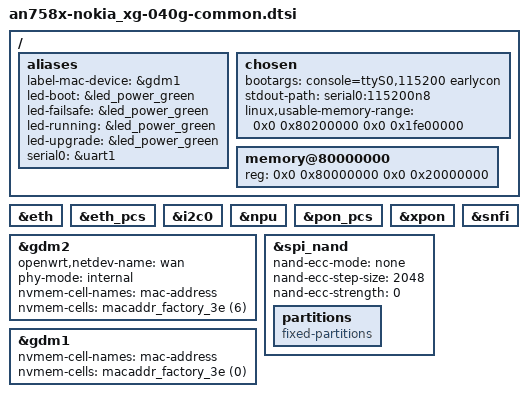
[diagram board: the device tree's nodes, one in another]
// SPDX-License-Identifier: GPL-2.0-only OR MIT

/ {
	aliases {
		label-mac-device = &gdm1;

		led-boot = &led_power_green;
		led-failsafe = &led_power_green;
		led-running = &led_power_green;
		led-upgrade = &led_power_green;

		serial0 = &uart1;
	};

	chosen {
		bootargs = "console=ttyS0,115200 earlycon";
		stdout-path = "serial0:115200n8";
		linux,usable-memory-range =
			<0x0 0x80200000 0x0 0x1fe00000>;
	};

	memory@80000000 {
		device_type = "memory";
		reg = <0x0 0x80000000 0x0 0x20000000>;
	};
};

&eth {
	status = "okay";
};

&eth_pcs {
	status = "okay";
};

&i2c0 {
	status = "okay";
};

&npu {
	status = "okay";
};

&pon_pcs {
	status = "okay";
};

&gdm2 {
	/*
	 * PON WAN port: gdm2 is the Ethernet MAC wired to the pon_pcs PCS
	 * (see an7581.dtsi: gdm2 has pcs-handle = <&pon_pcs>). The XPON driver
	 * (kmod-xpon-portable) creates the PON netdevice and drives the GPON
	 * MAC at 0x1fb64000; gdm2 is the CPU-side data path for WAN traffic
	 * once the ONU reaches O5 (operational) state.
	 *
	 * phy-mode "internal" because the PON MAC↔PCS link is on-chip.
	 * Label "wan" so 02_network can bind the WAN interface to it.
	 */
	status = "okay";

	openwrt,netdev-name = "wan";
	phy-mode = "internal";

	nvmem-cell-names = "mac-address";
	nvmem-cells = <&macaddr_factory_3e (6)>;
};

&xpon {
	status = "okay";
};

&snfi {
	status = "okay";
};

&spi_nand {
	/*
	 *  ECC must be aligned with bootloader to prevent read errors.
	 *  Stock fw also uses NAND_ECC_NONE.
	 */
	nand-ecc-mode = "none";
	nand-ecc-step-size = <2048>;
	nand-ecc-strength = <0>;

	partitions: partitions {
		compatible = "fixed-partitions";
		#address-cells = <1>;
		#size-cells = <1>;
	};
};

&gdm1 {
	status = "okay";

	nvmem-cell-names = "mac-address";
	nvmem-cells = <&macaddr_factory_3e (0)>;
};
